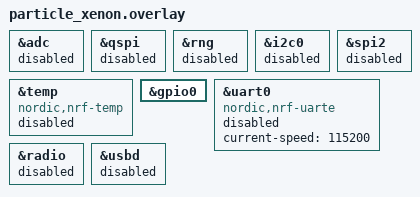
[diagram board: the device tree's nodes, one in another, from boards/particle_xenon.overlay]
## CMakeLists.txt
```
# SPDX-License-Identifier: Apache-2.0

cmake_minimum_required(VERSION 3.20.0)
find_package(Zephyr REQUIRED HINTS $ENV{ZEPHYR_BASE})
project(blinky)

target_include_directories(app PRIVATE include)

target_sources(app PRIVATE 
    src/main.cpp
    src/gpio_led.cpp
    )
```

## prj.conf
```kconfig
CONFIG_GPIO=y
CONFIG_LOG=y
CONFIG_USE_SEGGER_RTT=y
```

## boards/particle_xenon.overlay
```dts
/*
 * Copyright (c) 2020, Nordic Semiconductor ASA
 *
 * SPDX-License-Identifier: Apache-2.0
 */

&adc {
	status = "disabled";
};

&qspi {
	status = "disabled";
};

&rng {
	status = "disabled";
};


&i2c0 {
	status = "disabled";
};

&spi2 {
	status = "disabled";
};


&temp {
	compatible = "nordic,nrf-temp";
	status = "disabled";
};

&gpio0 {
	status = "okay";
};

&uart0 { 
	compatible = "nordic,nrf-uarte";
	current-speed = <115200>;
	status = "disabled";
};

&radio {
	status = "disabled";
};

&usbd {
	status = "disabled";
};
```

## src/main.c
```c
/*
 * Copyright (c) 2016 Intel Corporation
 *
 * SPDX-License-Identifier: Apache-2.0
 */

#include <zephyr/kernel.h>
#include <zephyr/drivers/gpio.h>
#include <zephyr/drivers/led.h>


const struct device *status_red_led = DEVICE_DT_GET(DT_PARENT(DT_ALIAS(led0)));

int main(void)
{
	int ret;

	ret = led_on(status_red_led, 0);
}
```

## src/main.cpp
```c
/*
 * Copyright (c) 2016 Intel Corporation
 *
 * SPDX-License-Identifier: Apache-2.0
 */

#include <zephyr/kernel.h>
#include <zephyr/device.h>
#include <zephyr/devicetree.h>
#include <zephyr/drivers/gpio.h>
#include <zephyr/logging/log.h>

#include <gpio_led.h>

LOG_MODULE_REGISTER(app, LOG_LEVEL_DBG);

// constexpr gpio_dt_spec status_red_led = GPIO_DT_SPEC_GET(DT_NODELABEL(status_red), gpios);
// constexpr gpio_dt_spec status_blue_led = GPIO_DT_SPEC_GET(DT_NODELABEL(status_blue), gpios);
// constexpr gpio_dt_spec status_green_led = GPIO_DT_SPEC_GET(DT_NODELABEL(status_green), gpios);
// constexpr gpio_dt_spec user_led = GPIO_DT_SPEC_GET(DT_NODELABEL(user_led), gpios);

void timer_stop(k_timer *timer)
{
    const auto led = static_cast<GPIO_LED*>(timer->user_data);
    led->off();
}

void timer_handler(k_timer *timer)
{
    // gpio_pin_toggle_dt(&status_green_led);
    auto led = static_cast<GPIO_LED*>(timer->user_data);
    led->toggle();
}

k_timer green_timer {};
k_timer red_timer {};
k_timer blue_timer {};

int main()
{
    GPIO_LED green { GPIO_DT_SPEC_GET(DT_NODELABEL(status_red), gpios) };
    GPIO_LED red { GPIO_DT_SPEC_GET(DT_NODELABEL(status_green), gpios) };
    GPIO_LED blue { GPIO_DT_SPEC_GET(DT_NODELABEL(user_led), gpios) };
    
    k_timer_init(&green_timer, timer_handler, timer_stop);
    k_timer_init(&red_timer, timer_handler, timer_stop);
    k_timer_init(&blue_timer, timer_handler, timer_stop);

    green_timer.user_data = static_cast<void*>(&green);
    red_timer.user_data = static_cast<void*>(&red);
    blue_timer.user_data = static_cast<void*>(&blue);

    k_timer_start(&green_timer, K_MSEC(100), K_MSEC(500));
    k_timer_start(&red_timer, K_MSEC(600), K_MSEC(500));
    k_timer_start(&blue_timer, K_MSEC(1), K_MSEC(500));

    while (true) {
        k_sleep(K_FOREVER);
    }
}
```

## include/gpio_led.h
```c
#pragma once

#include <zephyr/devicetree.h>
#include <zephyr/drivers/gpio.h>

class GPIO_LED
{
  public:
    GPIO_LED(const gpio_dt_spec &led, const uint32_t flags = GPIO_OUTPUT_INACTIVE);

    void on();
    void off();
    void toggle();

  private:
    const gpio_dt_spec _led;
};
```

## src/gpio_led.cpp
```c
#include <cstddef>
#include <gpio_led.h>

GPIO_LED::GPIO_LED(const gpio_dt_spec &led, const uint32_t flags) : _led {led} {
    if (device_is_ready(_led.port)) {
        gpio_pin_configure_dt(&_led, flags);
    }
}

void GPIO_LED::on()
{
    gpio_pin_set_dt(&_led, true);
}

void GPIO_LED::off()
{
    gpio_pin_set_dt(&_led, false);
}

void GPIO_LED::toggle()
{
    gpio_port_toggle_bits(_led.port, static_cast<gpio_port_pins_t>(BIT(_led.pin)));
}
```
